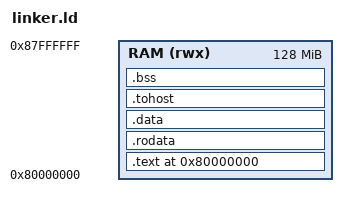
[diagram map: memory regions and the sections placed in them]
ENTRY(_start)

MEMORY {
    RAM (rwx) : ORIGIN = 0x80000000, LENGTH = 128M
}

SECTIONS {
    . = 0x80000000;

    .text : {
        *(.text.entry)
        *(.text*)
    } > RAM

    .rodata : { *(.rodata*) } > RAM
    .data   : { *(.data*)   } > RAM

    .tohost : {
        . = ALIGN(8);
        PROVIDE(tohost   = .); . += 8;
        PROVIDE(fromhost = .); . += 8;
    } > RAM

    .bss : { *(.bss*) } > RAM

    _end = .;
}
